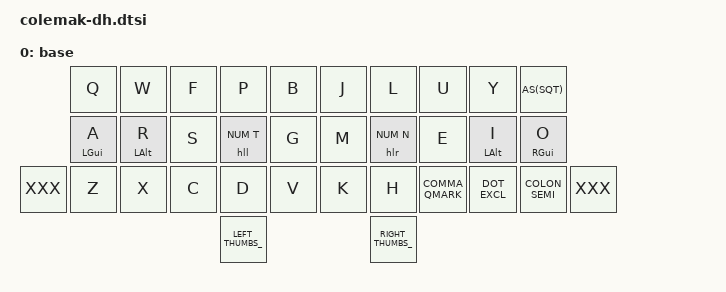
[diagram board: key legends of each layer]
/**
 * Alpha Layer - Colemak-DH
 */

/ {
    keymap {
        compatible = "zmk,keymap";

        colemak_dh {
			display-name = "base";
            bindings = <
//                ╭─────────────┬─────────────┬─────────────┬─────────────┬─────────────╮   ╭─────────────┬─────────────┬─────────────┬─────────────┬─────────────╮
                   &kp Q         &kp W         &kp F         &kp P         &kp B             &kp J         &kp L         &kp U         &kp Y         AS(SQT)
//                ├─────────────┼─────────────┼─────────────┼─────────────┼─────────────┤   ├─────────────├─────────────┼─────────────┼─────────────┼─────────────┤
                   &hml LGUI A   &hml LALT R   &kp S         &hll NUM T    &kp G             &kp M         &hlr NUM N    &kp E         &hmr LALT I   &hmr RGUI O
//  ╭─────────────┬─────────────┼─────────────┼─────────────┼─────────────┼─────────────┤   ├─────────────├─────────────┼─────────────┼─────────────┼─────────────┬─────────────╮
     XXX           &kp Z         &kp X         &kp C         &kp D         &kp V             &kp K         &kp H         COMMA_QMARK   DOT_EXCL      COLON_SEMI    XXX
//  ╰─────────────┴─────────────┴─────────────┼─────────────┼─────────────┼─────────────┤   ├─────────────├─────────────┼─────────────┼─────────────┴─────────────┴─────────────╯
                                                             _LEFT_THUMBS_                                _RIGHT_THUMBS_
//                                            ╰─────────────┴─────────────┴─────────────╯   ╰─────────────┴─────────────┴─────────────╯
            >;
		};
    };
};
